# CY8C5868AXI_LP032 register map
File version: 0.1
Registers are 8-bit, read-write, no defined reset value unless marked. A register's access mark holds for its fields unless they carry their own. Offsets are from the block's base; [hi:lo] are bit positions; {n}, {i} and the like mark numbered series; 'fields as' and 'values as' point back to an identical list.

## SAR1 — SAR ADC
Base 0x40004614
0x00 SAR_TR0 — SAR trim register
{0x12EC+i} SAR_CSR{i} (i=0..6) — SAR status and control register {i}
0x150C SAR_SW0 — SAR Analog Routing Register 0
{0x150C+i} SAR_SW{i} (i=2..4) — SAR Analog Routing Register {i}
0x1512 SAR_SW6 — SAR Analog Routing Register 6
0x1513 SAR_CLK — SAR Clock Selection Register
0x158C SAR_WRK 16-bit — SAR working register

## VDAC1_Flwr
Base 0x400043A4
0x00 PM_ACT_CFG4 — Active Power Mode Configuration Register 4
  [3:0] EN_OPAMP — Enables subsystems during active power mode
    0=Blk_0 (Enables analog linear output buffer for Opamp block 0); 2=Blk_1 (Enables analog linear output buffer for Opamp block 1); 4=Blk_2 (Enables analog linear output buffer for Opamp block 2); 8=Blk_3 (Enables analog linear output buffer for Opamp block 3)
0x10 PM_STBY_CFG4 — Standby Power Mode Configuration Register 4
  [3:0] EN_OPAMP — Enables subsystems during standby power mode
    values as PM_ACT_CFG4.EN_OPAMP
0x280 OPAMP__TR0 — Analog Output Buffer Trim Register 0
  [4:0] offset_trim — Offset Trim: 420uV typical step size; +/- 6.8mV offset trimmable range
0x281 OPAMP__TR1 — Analog Output Buffer Trim Register 1
0x14B8 OPAMP__CR — Analog Output Buffer Configuration Register
  [1:0] pwr_mode — Power Mode
    0=Default_Fast (Default Power mode Fast); 1=Slow (Power Mode Slow); 2=Medium (Power Mode Medium); 3=Fast (Power Mode Fast)
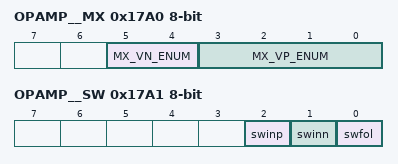
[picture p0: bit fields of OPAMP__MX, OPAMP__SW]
0x17A0 OPAMP__MX — Analog Buffer Input Selection Register
  [5:4] MX_VN_ENUM — MUX select VN (Negative terminal input)
    0=OPAMP0_MX_VN_DEFAULT (Default - Not Connected (NC)); 1=OPAMP0_MX_VN_AG4 (MUX Selection AGL(4)); 2=OPAMP0_MX_VN_AG6 (MUX Selection AGL(6)); 3=OPAMP0_MX_VN_0x3 (Reserved (NC))
  [3:0] MX_VP_ENUM — MUX select VP (Positive terminal input)
    0=OPAMP0_MX_VP_DEFAULT (Default - Not Connected (NC)); {v}=OPAMP0_MX_VP_AG{v+3} (MUX Selection AGL({v+3})) (v=1..4); {v}=OPAMP0_MX_VP_ABUS{v-5} (MUX Selection ABUSL({v-5})) (v=5..8); 9=OPAMP0_MX_VP_VREF (MUX Selection: OPAMP Voltage Reference); {v}=OPAMP0_MX_VP_H_{0x0+v} (Reserved (NC)) (v=10..15)
0x17A1 OPAMP__SW — Analog Buffer Routing Switch Register
  [2] swinp — Switch Enable Positive Input
  [1] swinn — Switch Enable Negative Input
  [0] swfol — Switch Enable Follow

## VDAC2_Flwr
Base 0x400043A4
0x00 PM_ACT_CFG4 — Active Power Mode Configuration Register 4
  [3:0] EN_OPAMP — Enables subsystems during active power mode
    0=Blk_0 (Enables analog linear output buffer for Opamp block 0); 2=Blk_1 (Enables analog linear output buffer for Opamp block 1); 4=Blk_2 (Enables analog linear output buffer for Opamp block 2); 8=Blk_3 (Enables analog linear output buffer for Opamp block 3)
0x10 PM_STBY_CFG4 — Standby Power Mode Configuration Register 4
  [3:0] EN_OPAMP — Enables subsystems during standby power mode
    values as PM_ACT_CFG4.EN_OPAMP
0x27E OPAMP__TR0 — Analog Output Buffer Trim Register 0
  [4:0] offset_trim — Offset Trim: 420uV typical step size; +/- 6.8mV offset trimmable range
0x27F OPAMP__TR1 — Analog Output Buffer Trim Register 1
0x14B6 OPAMP__CR — Analog Output Buffer Configuration Register
  [1:0] pwr_mode — Power Mode
    0=Default_Fast (Default Power mode Fast); 1=Slow (Power Mode Slow); 2=Medium (Power Mode Medium); 3=Fast (Power Mode Fast)
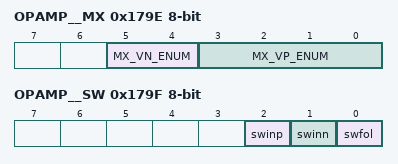
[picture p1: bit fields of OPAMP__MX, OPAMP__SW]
0x179E OPAMP__MX — Analog Buffer Input Selection Register
  [5:4] MX_VN_ENUM — MUX select VN (Negative terminal input)
    0=OPAMP0_MX_VN_DEFAULT (Default - Not Connected (NC)); 1=OPAMP0_MX_VN_AG4 (MUX Selection AGL(4)); 2=OPAMP0_MX_VN_AG6 (MUX Selection AGL(6)); 3=OPAMP0_MX_VN_0x3 (Reserved (NC))
  [3:0] MX_VP_ENUM — MUX select VP (Positive terminal input)
    0=OPAMP0_MX_VP_DEFAULT (Default - Not Connected (NC)); {v}=OPAMP0_MX_VP_AG{v+3} (MUX Selection AGL({v+3})) (v=1..4); {v}=OPAMP0_MX_VP_ABUS{v-5} (MUX Selection ABUSL({v-5})) (v=5..8); 9=OPAMP0_MX_VP_VREF (MUX Selection: OPAMP Voltage Reference); {v}=OPAMP0_MX_VP_H_{0x0+v} (Reserved (NC)) (v=10..15)
0x179F OPAMP__SW — Analog Buffer Routing Switch Register
  [2] swinp — Switch Enable Positive Input
  [1] swinn — Switch Enable Negative Input
  [0] swfol — Switch Enable Follow
